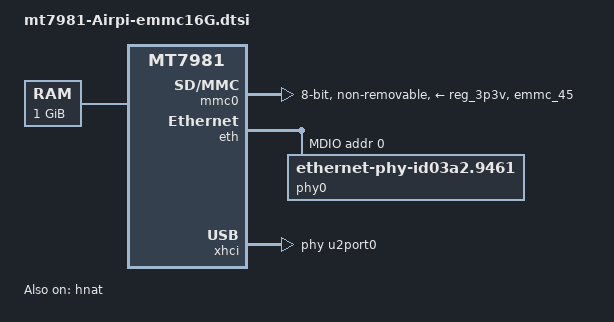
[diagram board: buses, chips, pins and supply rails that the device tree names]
#include "mt7981-Airpi-emmc16G-common.dtsi"

/ {
	compatible = "7981-Airpi", "mediatek,mt7981-emmc-rfb";
	chosen {
		bootargs = "console=ttyS0,115200n1 rootwait loglevel=8  \
				earlycon=uart8250,mmio32,0x11002000 \
				root=PARTLABEL=rootfs rootfstype=squashfs,f2fs";
	};
	memory {
		// fpga ddr4: 1GB
		reg = <0 0x40000000 0 0x40000000>;
	};
};

&mmc0 {
         pinctrl-names = "default", "state_uhs";
         pinctrl-0 = <&mmc0_pins_default>;
         pinctrl-1 = <&mmc0_pins_uhs>;
         bus-width = <8>;
         max-frequency = <52000000>;
         cap-mmc-highspeed;
         vmmc-supply = <&reg_3p3v>;
         non-removable;
         status = "okay";
};

&spi1 {
	pinctrl-names = "default";
	pinctrl-0 = <&spic_pins>;
	status = "disabled";
};

&pio {

	spic_pins: spi1-pins {
		mux {
			function = "spi";
			groups = "spi1_1";
		};
	};

	mmc0_pins_default: mmc0-pins-default {
		mux {
			function = "flash";
			groups = "emmc_45";
		};
	};

	mmc0_pins_uhs: mmc0-pins-uhs {
		mux {
			function = "flash";
			groups = "emmc_45";
		};
	};
};

&eth {
	status = "okay";

	gmac0: mac@0 {
		compatible = "mediatek,eth-mac";
		reg = <0>;
		phy-mode = "2500base-x";
		ext-phy-reg = <1>;
 		ext-phy-reset-gpios = <&pio 39 0>;
		fixed-link {
                        speed = <2500>;
                        full-duplex;
                        pause;
                };		
	};

	gmac1: mac@1 {
		compatible = "mediatek,eth-mac";
		reg = <1>;
		phy-mode = "gmii";
		phy-handle = <&phy0>;
	};

	mdio: mdio-bus {
		#address-cells = <1>;
		#size-cells = <0>;

		phy0: ethernet-phy@0 {
			compatible = "ethernet-phy-id03a2.9461";
			reg = <0>;
			phy-mode = "gmii";
			nvmem-cells = <&phy_calibration>;
			nvmem-cell-names = "phy-cal-data";
		};



	};
};

&xhci {
	mediatek,u3p-dis-msk = <0x0>;
	phys = <&u2port0 PHY_TYPE_USB2>,
	       <&u3port0 PHY_TYPE_USB3>;
	status = "okay";
};

&hnat {
	mtketh-wan = "eth0";
	mtketh-lan = "eth1";
	mtketh-max-gmac = <2>;
	status = "okay";
};
